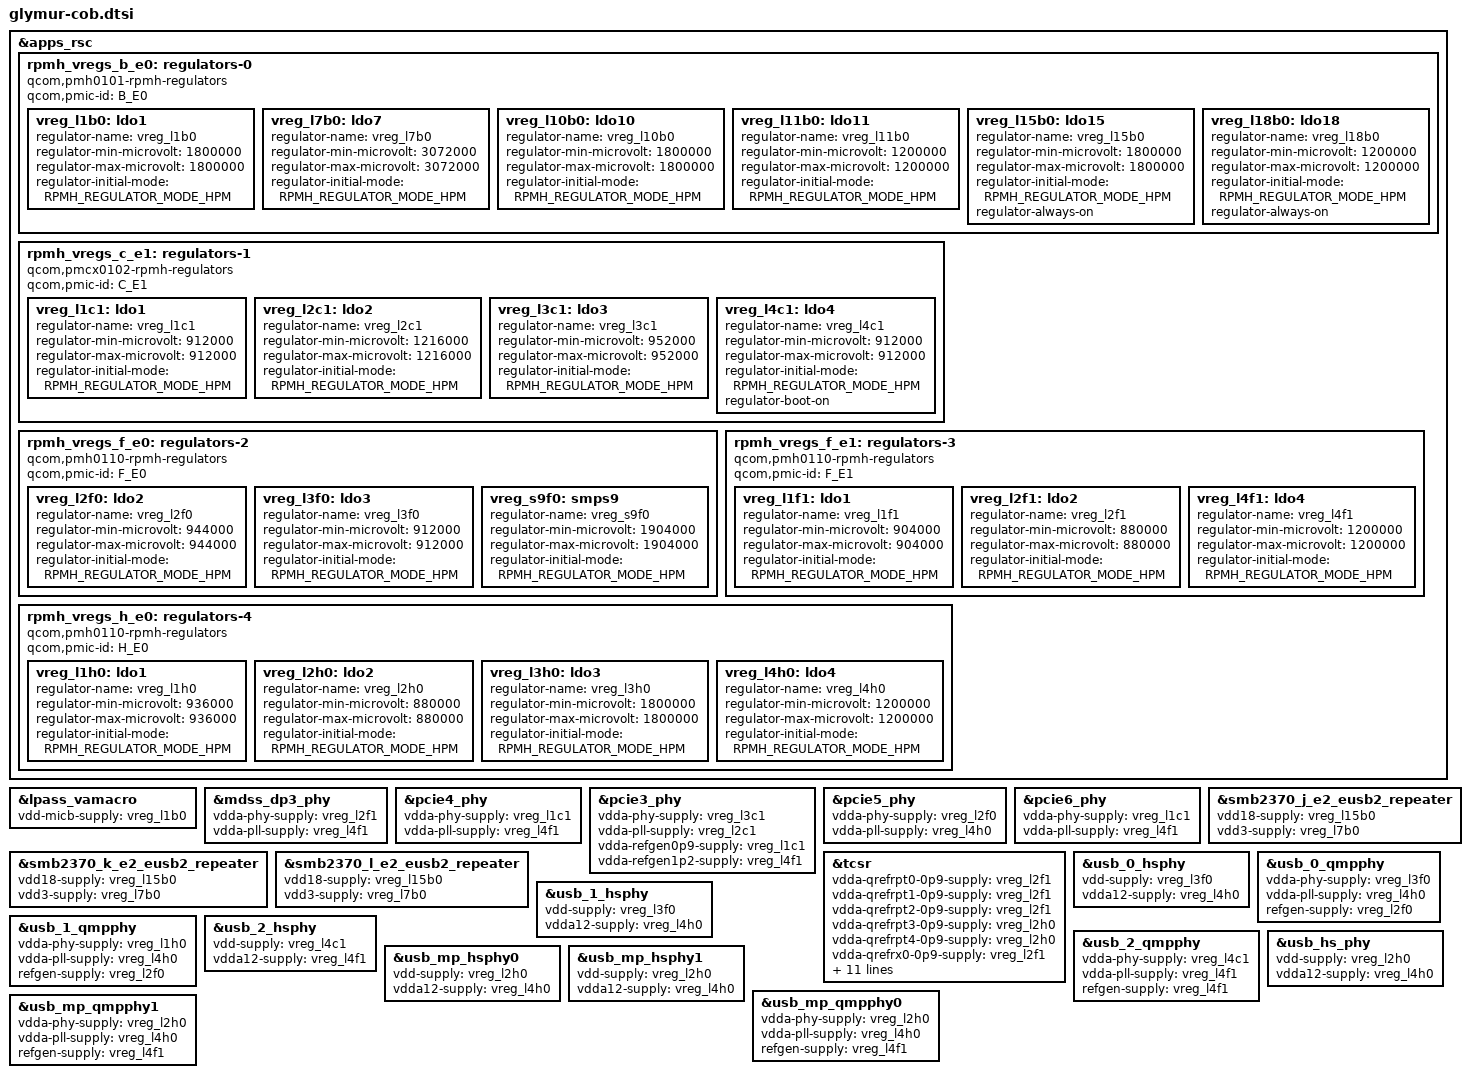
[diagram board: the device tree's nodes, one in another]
// SPDX-License-Identifier: BSD-3-Clause
/*
 * Copyright (c) Qualcomm Technologies, Inc. and/or its subsidiaries.
 *
 * Common PMIC settings for on-SoC peripherals found on Glymur-CoB and
 * derived platforms.
 */

#include "glymur.dtsi"
#include "pmcx0102.dtsi"        /* SPMI0: SID-2/3 SPMI1: SID-2/3 */
#include "pmh0101.dtsi"         /* SPMI0: SID-1                  */
#include "pmh0110-glymur.dtsi"  /* SPMI0: SID-5/7 SPMI1: SID-5   */
#include "pmh0104-glymur.dtsi"  /* SPMI0: SID-8/9 SPMI1: SID-11  */
#include "pmk8850.dtsi"         /* SPMI0: SID-0                  */
#include "smb2370.dtsi"         /* SPMI2: SID-9/10/11            */

&apps_rsc {
	rpmh_vregs_b_e0: regulators-0 {
		compatible = "qcom,pmh0101-rpmh-regulators";
		qcom,pmic-id = "B_E0";

		vreg_l1b0: ldo1 {
			regulator-name = "vreg_l1b0";
			regulator-min-microvolt = <1800000>;
			regulator-max-microvolt = <1800000>;
			regulator-initial-mode = <RPMH_REGULATOR_MODE_HPM>;
		};

		vreg_l7b0: ldo7 {
			regulator-name = "vreg_l7b0";
			regulator-min-microvolt = <3072000>;
			regulator-max-microvolt = <3072000>;
			regulator-initial-mode = <RPMH_REGULATOR_MODE_HPM>;
		};

		/* Pull-ups etc. */
		vreg_l10b0: ldo10 {
			regulator-name = "vreg_l10b0";
			regulator-min-microvolt = <1800000>;
			regulator-max-microvolt = <1800000>;
			regulator-initial-mode = <RPMH_REGULATOR_MODE_HPM>;
		};

		/* Pull-ups etc. */
		vreg_l11b0: ldo11 {
			regulator-name = "vreg_l11b0";
			regulator-min-microvolt = <1200000>;
			regulator-max-microvolt = <1200000>;
			regulator-initial-mode = <RPMH_REGULATOR_MODE_HPM>;
		};

		/* Pull-ups etc. */
		vreg_l15b0: ldo15 {
			regulator-name = "vreg_l15b0";
			regulator-min-microvolt = <1800000>;
			regulator-max-microvolt = <1800000>;
			regulator-initial-mode = <RPMH_REGULATOR_MODE_HPM>;
			/* Provides reference voltage for many undescribed components */
			regulator-always-on;
		};

		/* Pull-ups etc. */
		vreg_l18b0: ldo18 {
			regulator-name = "vreg_l18b0";
			regulator-min-microvolt = <1200000>;
			regulator-max-microvolt = <1200000>;
			regulator-initial-mode = <RPMH_REGULATOR_MODE_HPM>;
			/* Provides reference voltage for many undescribed components */
			regulator-always-on;
		};
	};

	rpmh_vregs_c_e1: regulators-1 {
		compatible = "qcom,pmcx0102-rpmh-regulators";
		qcom,pmic-id = "C_E1";

		vreg_l1c1: ldo1 {
			regulator-name = "vreg_l1c1";
			regulator-min-microvolt = <912000>;
			regulator-max-microvolt = <912000>;
			regulator-initial-mode = <RPMH_REGULATOR_MODE_HPM>;
		};

		vreg_l2c1: ldo2 {
			regulator-name = "vreg_l2c1";
			regulator-min-microvolt = <1216000>;
			regulator-max-microvolt = <1216000>;
			regulator-initial-mode = <RPMH_REGULATOR_MODE_HPM>;
		};

		vreg_l3c1: ldo3 {
			regulator-name = "vreg_l3c1";
			regulator-min-microvolt = <952000>;
			regulator-max-microvolt = <952000>;
			regulator-initial-mode = <RPMH_REGULATOR_MODE_HPM>;
		};

		vreg_l4c1: ldo4 {
			regulator-name = "vreg_l4c1";
			regulator-min-microvolt = <912000>;
			regulator-max-microvolt = <912000>;
			regulator-initial-mode = <RPMH_REGULATOR_MODE_HPM>;
			regulator-boot-on;
		};
	};

	rpmh_vregs_f_e0: regulators-2 {
		compatible = "qcom,pmh0110-rpmh-regulators";
		qcom,pmic-id = "F_E0";

		vreg_l2f0: ldo2 {
			regulator-name = "vreg_l2f0";
			regulator-min-microvolt = <944000>;
			regulator-max-microvolt = <944000>;
			regulator-initial-mode = <RPMH_REGULATOR_MODE_HPM>;
		};

		vreg_l3f0: ldo3 {
			regulator-name = "vreg_l3f0";
			regulator-min-microvolt = <912000>;
			regulator-max-microvolt = <912000>;
			regulator-initial-mode = <RPMH_REGULATOR_MODE_HPM>;
		};

		/* Voltage input for PMCX0104 */
		vreg_s9f0: smps9 {
			regulator-name = "vreg_s9f0";
			regulator-min-microvolt = <1904000>;
			regulator-max-microvolt = <1904000>;
			regulator-initial-mode = <RPMH_REGULATOR_MODE_HPM>;
		};
	};

	rpmh_vregs_f_e1: regulators-3 {
		compatible = "qcom,pmh0110-rpmh-regulators";
		qcom,pmic-id = "F_E1";

		vreg_l1f1: ldo1 {
			regulator-name = "vreg_l1f1";
			regulator-min-microvolt = <904000>;
			regulator-max-microvolt = <904000>;
			regulator-initial-mode = <RPMH_REGULATOR_MODE_HPM>;
		};

		vreg_l2f1: ldo2 {
			regulator-name = "vreg_l2f1";
			regulator-min-microvolt = <880000>;
			regulator-max-microvolt = <880000>;
			regulator-initial-mode = <RPMH_REGULATOR_MODE_HPM>;
		};

		vreg_l4f1: ldo4 {
			regulator-name = "vreg_l4f1";
			regulator-min-microvolt = <1200000>;
			regulator-max-microvolt = <1200000>;
			regulator-initial-mode = <RPMH_REGULATOR_MODE_HPM>;
		};
	};

	rpmh_vregs_h_e0: regulators-4 {
		compatible = "qcom,pmh0110-rpmh-regulators";
		qcom,pmic-id = "H_E0";

		vreg_l1h0: ldo1 {
			regulator-name = "vreg_l1h0";
			regulator-min-microvolt = <936000>;
			regulator-max-microvolt = <936000>;
			regulator-initial-mode = <RPMH_REGULATOR_MODE_HPM>;
		};

		vreg_l2h0: ldo2 {
			regulator-name = "vreg_l2h0";
			regulator-min-microvolt = <880000>;
			regulator-max-microvolt = <880000>;
			regulator-initial-mode = <RPMH_REGULATOR_MODE_HPM>;
		};

		/* DDR, QFPROM */
		vreg_l3h0: ldo3 {
			regulator-name = "vreg_l3h0";
			regulator-min-microvolt = <1800000>;
			regulator-max-microvolt = <1800000>;
			regulator-initial-mode = <RPMH_REGULATOR_MODE_HPM>;
		};

		vreg_l4h0: ldo4 {
			regulator-name = "vreg_l4h0";
			regulator-min-microvolt = <1200000>;
			regulator-max-microvolt = <1200000>;
			regulator-initial-mode = <RPMH_REGULATOR_MODE_HPM>;
		};
	};
};

&lpass_vamacro {
	vdd-micb-supply = <&vreg_l1b0>;
};

&mdss_dp3_phy {
	vdda-phy-supply = <&vreg_l2f1>;
	vdda-pll-supply = <&vreg_l4f1>;
};

&pcie4_phy {
	vdda-phy-supply = <&vreg_l1c1>;
	vdda-pll-supply = <&vreg_l4f1>;
};

&pcie3_phy {
	vdda-phy-supply = <&vreg_l3c1>;
	vdda-pll-supply = <&vreg_l2c1>;

	vdda-refgen0p9-supply = <&vreg_l1c1>;
	vdda-refgen1p2-supply = <&vreg_l4f1>;
};

&pcie5_phy {
	vdda-phy-supply = <&vreg_l2f0>;
	vdda-pll-supply = <&vreg_l4h0>;
};

&pcie6_phy {
	vdda-phy-supply = <&vreg_l1c1>;
	vdda-pll-supply = <&vreg_l4f1>;
};

&smb2370_j_e2_eusb2_repeater {
	vdd18-supply = <&vreg_l15b0>;
	vdd3-supply = <&vreg_l7b0>;
};

&smb2370_k_e2_eusb2_repeater {
	vdd18-supply = <&vreg_l15b0>;
	vdd3-supply = <&vreg_l7b0>;
};

&smb2370_l_e2_eusb2_repeater {
	vdd18-supply = <&vreg_l15b0>;
	vdd3-supply = <&vreg_l7b0>;
};

&tcsr {
	vdda-qrefrpt0-0p9-supply = <&vreg_l2f1>;
	vdda-qrefrpt1-0p9-supply = <&vreg_l2f1>;
	vdda-qrefrpt2-0p9-supply = <&vreg_l2f1>;
	vdda-qrefrpt3-0p9-supply = <&vreg_l2h0>;
	vdda-qrefrpt4-0p9-supply = <&vreg_l2h0>;
	vdda-qrefrx0-0p9-supply = <&vreg_l2f1>;
	vdda-qrefrx1-0p9-supply = <&vreg_l2f1>;
	vdda-qrefrx2-0p9-supply = <&vreg_l2f1>;
	vdda-qrefrx4-0p9-supply = <&vreg_l2h0>;
	vdda-qrefrx5-0p9-supply = <&vreg_l3f0>;
	vdda-qreftx0-0p9-supply = <&vreg_l3f0>;
	vdda-qreftx0-1p2-supply = <&vreg_l4h0>;
	vdda-qreftx1-0p9-supply = <&vreg_l1f1>;
	vdda-refgen3-0p9-supply = <&vreg_l2f0>;
	vdda-refgen3-1p2-supply = <&vreg_l4h0>;
	vdda-refgen4-0p9-supply = <&vreg_l1f1>;
	vdda-refgen4-1p2-supply = <&vreg_l4f1>;
};

&usb_0_hsphy {
	vdd-supply = <&vreg_l3f0>;
	vdda12-supply = <&vreg_l4h0>;
};

&usb_0_qmpphy {
	vdda-phy-supply = <&vreg_l3f0>;
	vdda-pll-supply = <&vreg_l4h0>;
	refgen-supply = <&vreg_l2f0>;
};

&usb_1_hsphy {
	vdd-supply = <&vreg_l3f0>;
	vdda12-supply = <&vreg_l4h0>;
};

&usb_1_qmpphy {
	vdda-phy-supply = <&vreg_l1h0>;
	vdda-pll-supply = <&vreg_l4h0>;
	refgen-supply = <&vreg_l2f0>;
};

&usb_2_hsphy {
	vdd-supply = <&vreg_l4c1>;
	vdda12-supply = <&vreg_l4f1>;
};

&usb_2_qmpphy {
	vdda-phy-supply = <&vreg_l4c1>;
	vdda-pll-supply = <&vreg_l4f1>;
	refgen-supply = <&vreg_l4f1>;
};

&usb_hs_phy {
	vdd-supply = <&vreg_l2h0>;
	vdda12-supply = <&vreg_l4h0>;
};

&usb_mp_hsphy0 {
	vdd-supply = <&vreg_l2h0>;
	vdda12-supply = <&vreg_l4h0>;
};

&usb_mp_hsphy1 {
	vdd-supply = <&vreg_l2h0>;
	vdda12-supply = <&vreg_l4h0>;
};

&usb_mp_qmpphy0 {
	vdda-phy-supply = <&vreg_l2h0>;
	vdda-pll-supply = <&vreg_l4h0>;
	refgen-supply = <&vreg_l4f1>;
};

&usb_mp_qmpphy1 {
	vdda-phy-supply = <&vreg_l2h0>;
	vdda-pll-supply = <&vreg_l4h0>;
	refgen-supply = <&vreg_l4f1>;
};
